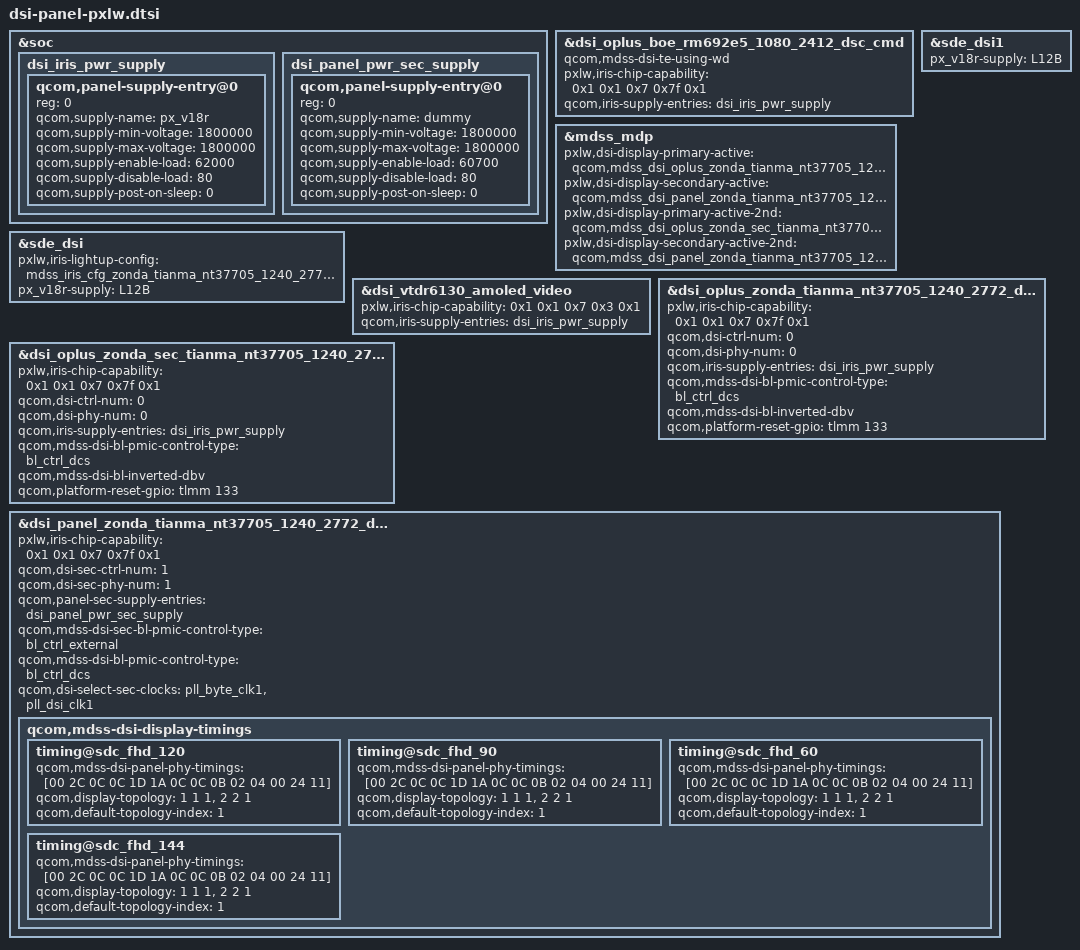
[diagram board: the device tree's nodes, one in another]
/* Copyright (c) 2020, Pixelworks
 *
 * This program is free software; you can redistribute it and/or modify
 * it under the terms of the GNU General Public License version 2 and
 * only version 2 as published by the Free Software Foundation.
 *
 * This program is distributed in the hope that it will be useful,
 * but WITHOUT ANY WARRANTY; without even the implied warranty of
 * MERCHANTABILITY or FITNESS FOR A PARTICULAR PURPOSE.  See the
 * GNU General Public License for more details.
 */

#include "pxlw-iris7-cfg-zonda-tianma-nt37705-1240-2772-dsc-cmd.dtsi"
#include "dsi-panel-zonda-tianma-nt37705-1240-2772-dsc-cmd-2nd.dtsi"

&soc {
	dsi_iris_pwr_supply: dsi_iris_pwr_supply {
		#address-cells = <1>;
		#size-cells = <0>;

		qcom,panel-supply-entry@0 {
			reg = <0>;
			qcom,supply-name = "px_v18r";
			qcom,supply-min-voltage = <1800000>;
			qcom,supply-max-voltage = <1800000>;
			qcom,supply-enable-load = <62000>;
			qcom,supply-disable-load = <80>;
			qcom,supply-post-on-sleep = <0>;
		};
	};

	/* avoid failed to parse power config */
	dsi_panel_pwr_sec_supply: dsi_panel_pwr_sec_supply {
		#address-cells = <1>;
		#size-cells = <0>;

		qcom,panel-supply-entry@0 {
			reg = <0>;
			qcom,supply-name = "dummy";
			qcom,supply-min-voltage = <1800000>;
			qcom,supply-max-voltage = <1800000>;
			qcom,supply-enable-load = <60700>;
			qcom,supply-disable-load = <80>;
			qcom,supply-post-on-sleep = <0>;
		};
	};
};

&dsi_oplus_boe_rm692e5_1080_2412_dsc_cmd {
	qcom,mdss-dsi-te-using-wd;
	pxlw,iris-chip-capability = <0x1 0x1 0x7 0x7f 0x1>;
	qcom,iris-supply-entries = <&dsi_iris_pwr_supply>;
};

/* select panel */
&mdss_mdp {
	pxlw,dsi-display-primary-active = "qcom,mdss_dsi_oplus_zonda_tianma_nt37705_1240_2772_dsc_cmd";
	pxlw,dsi-display-secondary-active = "qcom,mdss_dsi_panel_zonda_tianma_nt37705_1240_2772_dsc_cmd_2nd";
	pxlw,dsi-display-primary-active-2nd = "qcom,mdss_dsi_oplus_zonda_sec_tianma_nt37705_1240_2772_dsc_cmd";
	pxlw,dsi-display-secondary-active-2nd = "qcom,mdss_dsi_panel_zonda_tianma_nt37705_1240_2772_dsc_cmd_2nd";
};

&sde_dsi {
	pxlw,iris-lightup-config = <&mdss_iris_cfg_zonda_tianma_nt37705_1240_2772_dsc_cmd>;
	px_v18r-supply = <&L12B>;
};

&sde_dsi1 {
	px_v18r-supply = <&L12B>;
};

&dsi_vtdr6130_amoled_video {
	pxlw,iris-chip-capability = <0x1 0x1 0x7 0x3 0x1>;
	qcom,iris-supply-entries = <&dsi_iris_pwr_supply>;
};


&dsi_oplus_zonda_tianma_nt37705_1240_2772_dsc_cmd {
	pxlw,iris-chip-capability = <0x1 0x1 0x7 0x7f 0x1>;
	qcom,dsi-ctrl-num = <0>;
	qcom,dsi-phy-num = <0>;
	qcom,iris-supply-entries = <&dsi_iris_pwr_supply>;
	qcom,mdss-dsi-bl-pmic-control-type = "bl_ctrl_dcs";
	qcom,mdss-dsi-bl-inverted-dbv;
	qcom,platform-reset-gpio = <&tlmm 133 0>;
};

&dsi_oplus_zonda_sec_tianma_nt37705_1240_2772_dsc_cmd {
	pxlw,iris-chip-capability = <0x1 0x1 0x7 0x7f 0x1>;
	qcom,dsi-ctrl-num = <0>;
	qcom,dsi-phy-num = <0>;
	qcom,iris-supply-entries = <&dsi_iris_pwr_supply>;
	qcom,mdss-dsi-bl-pmic-control-type = "bl_ctrl_dcs";
	qcom,mdss-dsi-bl-inverted-dbv;
	qcom,platform-reset-gpio = <&tlmm 133 0>;
};

&dsi_panel_zonda_tianma_nt37705_1240_2772_dsc_cmd_2nd {
	pxlw,iris-chip-capability = <0x1 0x1 0x7 0x7f 0x1>;
	qcom,dsi-sec-ctrl-num = <1>;
	qcom,dsi-sec-phy-num = <1>;
	qcom,panel-sec-supply-entries = <&dsi_panel_pwr_sec_supply>;
	qcom,mdss-dsi-sec-bl-pmic-control-type = "bl_ctrl_external";
	qcom,mdss-dsi-bl-pmic-control-type = "bl_ctrl_dcs";
	qcom,dsi-select-sec-clocks = "pll_byte_clk1", "pll_dsi_clk1";
	qcom,mdss-dsi-display-timings {
		timing@sdc_fhd_120 { /* FHD+ 120hz */
			qcom,mdss-dsi-panel-phy-timings = [00 2C 0C 0C 1D 1A 0C 0C 0B 02 04 00 24 11];
			qcom,display-topology = <1 1 1>,<2 2 1>;
			qcom,default-topology-index = <1>;
		};
		timing@sdc_fhd_90 { /* FHD+ 90hz */
			qcom,mdss-dsi-panel-phy-timings = [00 2C 0C 0C 1D 1A 0C 0C 0B 02 04 00 24 11];
			qcom,display-topology = <1 1 1>,<2 2 1>;
			qcom,default-topology-index = <1>;
		};
		timing@sdc_fhd_60 { /* FHD+ 60hz */
			qcom,mdss-dsi-panel-phy-timings = [00 2C 0C 0C 1D 1A 0C 0C 0B 02 04 00 24 11];
			qcom,display-topology = <1 1 1>,<2 2 1>;
			qcom,default-topology-index = <1>;
		};
		timing@sdc_fhd_144 { /* FHD+ 144hz */
			qcom,mdss-dsi-panel-phy-timings = [00 2C 0C 0C 1D 1A 0C 0C 0B 02 04 00 24 11];
			qcom,display-topology = <1 1 1>,<2 2 1>;
			qcom,default-topology-index = <1>;
		};
	};
};

